# MDR1986VE3 register map
Vendor: Milandr; Series: ARMCM1; File version: 2.0
CPU: CM1 r1p0, little endian, no MPU, no FPU, 2 interrupt priority bits
Registers are 32-bit, read-write, reset 0x0 unless marked. A register's access mark holds for its fields unless they carry their own. Offsets are from the block's base; [hi:lo] are bit positions; {n}, {i} and the like mark numbered series; 'fields as' and 'values as' point back to an identical list.

## MDR_RST_CLOCK — CLock Control
Base 0x40020000
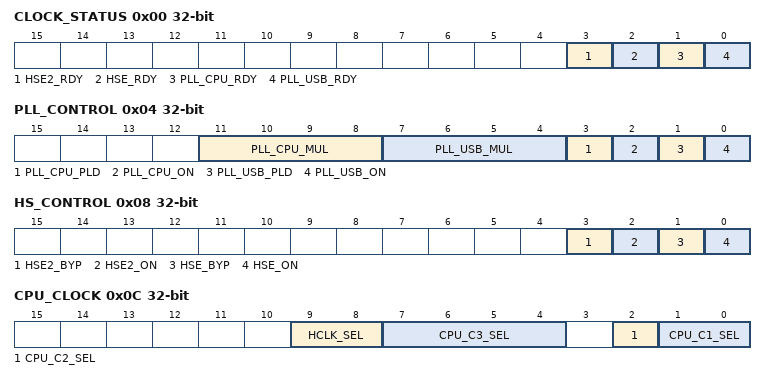
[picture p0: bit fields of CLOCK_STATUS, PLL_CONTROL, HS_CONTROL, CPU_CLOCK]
0x00 CLOCK_STATUS ro
  [3] HSE2_RDY — HSE2 generator ready
    0=NotReady (HSE2 not ready); 1=Ready (HSE2 ready)
  [2] HSE_RDY — HSE generator ready
    0=NotReady (HSE not ready); 1=Ready (HSE ready)
  [1] PLL_CPU_RDY — PLL CPU ready
    0=NotReady (PLL not ready); 1=Ready (PLL ready)
  [0] PLL_USB_RDY — PLL USP ready
    0=NotReady (PLL not ready); 1=Ready (PLL ready)
0x04 PLL_CONTROL
  [11:8] PLL_CPU_MUL — PLL CPU Mul, [x1 .. x16]
    0=PLL mul x1; {v}=x{v+1} (PLL mul x{v+1}) (v=1..8); 9=PLL mul x10; 10=PLL mul x11; {v}=x{v+1} (PLL mul x{v+1}) (v=11..15)
  [7:4] PLL_USB_MUL — PLL USB Mul, [x1 .. x16]
    values as PLL_CPU_MUL
  [3] PLL_CPU_PLD — PLL CPU Restart
    0=RestartOff (PLL restart inactive); 1=DoRestart (PLL Do Restart)
  [2] PLL_CPU_ON — PLL CPU Enable
    0=Off (PLL Off); 1=On (PLL On)
  [1] PLL_USB_PLD — PLL USB Restart
    values as PLL_CPU_PLD
  [0] PLL_USB_ON — PLL USB Enable
    0=Off (PLL Off); 1=On (PLL On)
0x08 HS_CONTROL — HSE Generator Control
  [3] HSE2_BYP — HSE2 Bypass Mode
    0=Off (HSE2 forms Clock from external oscillator); 1=On (HSE2 passes Clock from external generator)
  [2] HSE2_ON — HSE2 Enable
    0=Off (HSE2 Off); 1=On (HSE2 On)
  [1] HSE_BYP — HSE Bypass Mode
    0=Off (HSE forms Clock from external oscillator); 1=On (HSE passes Clock from external generator)
  [0] HSE_ON — HSE Enable
    0=Off (HSE Off); 1=On (HSE On)
0x0C CPU_CLOCK — CPU Clock Control
  [9:8] HCLK_SEL — Select Clock for CPU
    0=HSI (CPU clock is HSI); 1=CPU_C3 (CPU clock is CPU_C3 output); 2=LSE (CPU clock is LSE); 3=LSI (CPU clock is LSI)
  [7:4] CPU_C3_SEL — CPU_C2 mux output freq devider, [/1, /2, /4 .. /256]
    0b0xxx=div1 (div by 1); 8=div2 (div by 2); 9=div4 (div by 4); 10=div8 (div by 8); 11=div16 (div by 16); 12=div32 (div by 32); 13=div64 (div by 64); 14=div128 (div by 128); 15=div256 (div by 256)
  [2] CPU_C2_SEL — CPU_C2 mux freq select
    0=CPU_C1 (Freq from CPU_C1 mux direct); 1=PLLCPUo (Freq from CPU_C1 mux through PLL)
  [1:0] CPU_C1_SEL — CPU_C1 mux freq select
    0=HSI (CPU_C1 output is HSI); 1=HSI/2 (CPU_C1 output is HSI/2); 2=HSE (CPU_C1 output is HSE); 3=HSE/2 (CPU_C1 output is HSE/2)
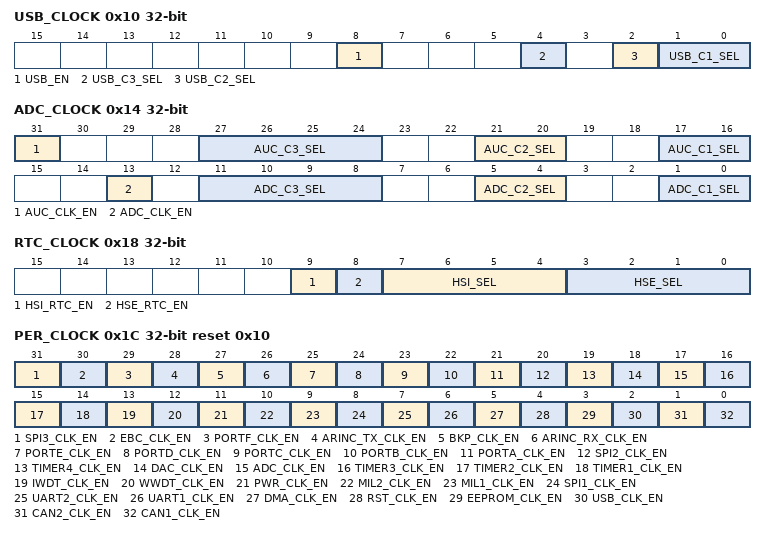
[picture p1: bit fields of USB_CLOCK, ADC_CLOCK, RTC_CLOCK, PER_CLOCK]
0x10 USB_CLOCK — USB Clock Control
  [8] USB_EN — USB Clock Enable
    0=Off (Clock Disabled); 1=On (Clock Enabled)
  [4] USB_C3_SEL — USB_C3 Input Select
    0=USB_C2 (C3 Input is freq from C2); 1=USB_C2_div2 (C3 Input is freq from C2/2)
  [2] USB_C2_SEL — USB_C2 mux freq select
    0=USB_C1 (Freq from CPU_C1 mux direct); 1=PLLUSBo (Freq from CPU_C1 mux through PLL_USB)
  [1:0] USB_C1_SEL — USB_C1 mux freq select
    0=HSI (USB_C1 output is HSI); 1=HSI/2 (USB_C1 output is HSI/2); 2=HSE (USB_C1 output is HSE); 3=HSE/2 (USB_C1 output is HSE/2)
0x14 ADC_CLOCK — ADC Clock Control
  [31] AUC_CLK_EN — AudioCodec Clock Enable
    0=Off (AUC clock disabled); 1=On (AUC clock enabled)
  [27:24] AUC_C3_SEL — AUC_C3 mux input select
    values as CPU_CLOCK.CPU_C3_SEL
  [21:20] AUC_C2_SEL — AUC_C2 mux input select
    0=AUC_C1 (AUC_C2 output is AUC_C1 select); 1=PLLCPUo (AUC_C2 output is PLLCPUo); 2=PLLUSBo (AUC_C2 output is PLLUSBo); 3=No signal from AUC_C2
  [17:16] AUC_C1_SEL — AUC_C1 mux input select
    values as CPU_CLOCK.CPU_C1_SEL
  [13] ADC_CLK_EN — ADC Clock Enable
    0=Off (ADC clock disabled); 1=On (ADC clock enabled)
  [11:8] ADC_C3_SEL — ADC_C2 mux output freq devider, [/1, /2, /4 .. /256]
    values as CPU_CLOCK.CPU_C3_SEL
  [5:4] ADC_C2_SEL — ADC_C2 mux freq select
    0=LSE (ADC_C2 output is LSE); 1=LSI (ADC_C2 output is LSI); 2=ADC_C1 (ADC_C2 output is ADC_C1); 3=HSI_C1 (ADC_C2 output is HSI_C1)
  [1:0] ADC_C1_SEL — ADC_C1 mux freq select
    0=CPU_C1 (ADC_C1 output is CPU_C1); 1=USB_C1 (ADC_C1 output is USB_C1); 2=CPU_C2 (ADC_C1 output is CPU_C2); 3=USB_C2 (ADC_C1 output is USB_C2)
0x18 RTC_CLOCK — RTC Clock Control
  [9] HSI_RTC_EN — RTC HSI Clock enable
    0=Off (RTC HSI Clock Disabled); 1=On (RTC HSI Clock Enabled)
  [8] HSE_RTC_EN — RTC HSE Clock enable
    0=Off (RTC HSE Clock Disabled); 1=On (RTC HSE Clock Enabled)
  [7:4] HSI_SEL — RTC HSI freq devider, [/1, /2, /4 .. /256]
    values as CPU_CLOCK.CPU_C3_SEL
  [3:0] HSE_SEL — RTC HSE freq devider, [/1, /2, /4 .. /256]
    values as CPU_CLOCK.CPU_C3_SEL
0x1C PER_CLOCK reset 0x10 — Peripherials Clock Control
  [all] fields
    0=Off (Clock Disabled); 1=On (Clock Enabled)
  [31] SPI3_CLK_EN — SPI3 Clock Enable
  [30] EBC_CLK_EN — External Bus Clock Enable
  [29] PORTF_CLK_EN — GPIO PORT_F Clock Enable
  [28] ARINC_TX_CLK_EN — ARINC_TX Clock Enable
  [27] BKP_CLK_EN — Backup Clock Enable
  [26] ARINC_RX_CLK_EN — ARINC_RX Clock Enable
  [25] PORTE_CLK_EN — GPIO PORT_E Clock Enable
  [24] PORTD_CLK_EN — GPIO PORT_D Clock Enable
  [23] PORTC_CLK_EN — GPIO PORT_C Clock Enable
  [22] PORTB_CLK_EN — GPIO PORT_B Clock Enable
  [21] PORTA_CLK_EN — GPIO PORT_A Clock Enable
  [20] SPI2_CLK_EN — SPI2 Clock Enable
  [19] TIMER4_CLK_EN — TIMER4 Clock Enable
  [18] DAC_CLK_EN — DAC Clock Enable
  [17] ADC_CLK_EN — ADC Clock Enable
  [16] TIMER3_CLK_EN — TIMER3 Clock Enable
  [15] TIMER2_CLK_EN — TIMER2 Clock Enable
  [14] TIMER1_CLK_EN — TIMER1 Clock Enable
  [13] IWDT_CLK_EN — IWDT Clock Enable
  [12] WWDT_CLK_EN — WWDT Clock Enable
  [11] PWR_CLK_EN — Power Clock Enable
  [10] MIL2_CLK_EN — MIL2 Clock Enable
  [9] MIL1_CLK_EN — MIL1 Clock Enable
  [8] SPI1_CLK_EN — SPI1 Clock Enable
  [7] UART2_CLK_EN — UART2 Clock Enable
  [6] UART1_CLK_EN — UART1 Clock Enable
  [5] DMA_CLK_EN — DMA Clock Enable
  [4] RST_CLK_EN — RST Clock Enable
  [3] EEPROM_CLK_EN — EEPROM Controller Clock Enable
  [2] USB_CLK_EN — USB Clock Enable
  [1] CAN2_CLK_EN — CAN2 Clock Enable
  [0] CAN1_CLK_EN — CAN1 Clock Enable
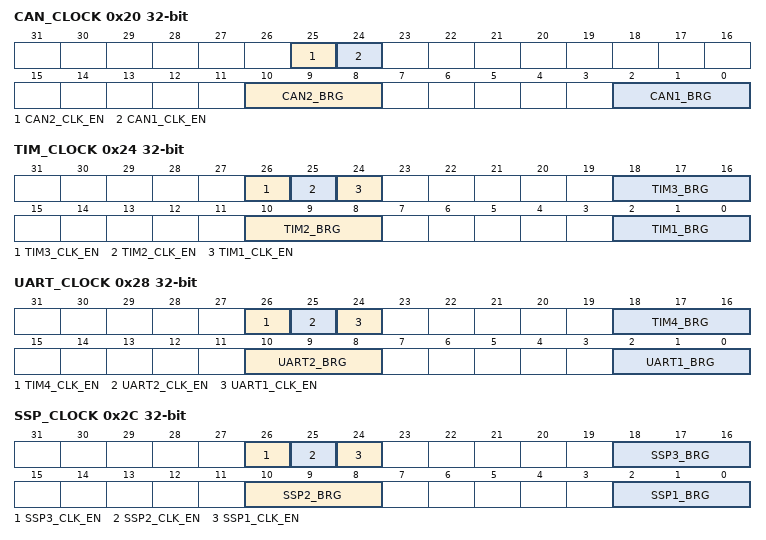
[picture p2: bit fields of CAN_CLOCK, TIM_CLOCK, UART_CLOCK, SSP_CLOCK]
0x20 CAN_CLOCK — CAN's Clock Control
  [25] CAN2_CLK_EN — CAN2_CLOCK enable
    0=Off (CAN2 Clock Disabled); 1=On (CAN2 Clock Enabled)
  [24] CAN1_CLK_EN — CAN1_CLOCK enable
    0=Off (CAN1 Clock Disabled); 1=On (CAN1 Clock Enabled)
  [10:8] CAN2_BRG — HCLK freq divider to get CAN2_CLOCK, [/1, /2, /4 .. /128]
    0=div1 (div by 1); 1=div2 (div by 2); 2=div4 (div by 4); 3=div8 (div by 8); 4=div16 (div by 16); 5=div32 (div by 32); 6=div64 (div by 64); 7=div128 (div by 128)
  [2:0] CAN1_BRG — HCLK divider to get CAN1_CLOCK, [/1, /2, /4 .. /128]
    values as CAN2_BRG
0x24 TIM_CLOCK — Timer's Clock Control
  [26] TIM3_CLK_EN — TIM3_CLOCK enable
    0=Off (Timer3 Clock Disabled); 1=On (Timer3 Clock Enabled)
  [25] TIM2_CLK_EN — TIM2_CLOCK enable
    0=Off (Timer2 Clock Disabled); 1=On (Timer2 Clock Enabled)
  [24] TIM1_CLK_EN — TIM1_CLOCK enable
    0=Off (Timer1 Clock Disabled); 1=On (Timer1 Clock Enabled)
  [18:16] TIM3_BRG — HCLK freq divider to get TIM3_CLOCK, [/1, /2, /4 .. /128]
    values as CAN_CLOCK.CAN2_BRG
  [10:8] TIM2_BRG — HCLK freq divider to get TIM2_CLOCK, [/1, /2, /4 .. /128]
    values as CAN_CLOCK.CAN2_BRG
  [2:0] TIM1_BRG — HCLK freq divider to get TIM1_CLOCK, [/1, /2, /4 .. /128]
    values as CAN_CLOCK.CAN2_BRG
0x28 UART_CLOCK — UART's Clock Control
  [26] TIM4_CLK_EN — TIM4_CLOCK enable
    0=Off (Timer4 Clock Disabled); 1=On (Timer4 Clock Enabled)
  [25] UART2_CLK_EN — UART2_CLOCK enable
    0=Off (UART2 Clock Disabled); 1=On (UART2 Clock Enabled)
  [24] UART1_CLK_EN — UART1_CLOCK enable
    0=Off (UART1 Clock Disabled); 1=On (UART1 Clock Enabled)
  [18:16] TIM4_BRG — HCLK freq divider to get TIM4_CLOCK, [/1, /2, /4 .. /128]
    values as CAN_CLOCK.CAN2_BRG
  [10:8] UART2_BRG — HCLK freq divider to get UART2_CLOCK, [/1, /2, /4 .. /128]
    values as CAN_CLOCK.CAN2_BRG
  [2:0] UART1_BRG — HCLK freq divider to get UART1_CLOCK, [/1, /2, /4 .. /128]
    values as CAN_CLOCK.CAN2_BRG
0x2C SSP_CLOCK — SSP's Clock Control
  [26] SSP3_CLK_EN — SSP3_CLOCK Enable
    0=Off (SSP3 Clock Disabled); 1=On (SSP3 Clock Enabled)
  [25] SSP2_CLK_EN — SSP2_CLOCK Enable
    0=Off (SSP2 Clock Disabled); 1=On (SSP2 Clock Enabled)
  [24] SSP1_CLK_EN — SSP1_CLOCK Enable
    0=Off (SSP1 Clock Disabled); 1=On (SSP1 Clock Enabled)
  [18:16] SSP3_BRG — HCLK freq divider to get SSP3_CLOCK, [/1, /2, /4 .. /128]
    values as CAN_CLOCK.CAN2_BRG
  [10:8] SSP2_BRG — HCLK freq divider to get SSP2_CLOCK, [/1, /2, /4 .. /128]
    values as CAN_CLOCK.CAN2_BRG
  [2:0] SSP1_BRG — HCLK freq divider to get SSP1_CLOCK, [/1, /2, /4 .. /128]
    values as CAN_CLOCK.CAN2_BRG
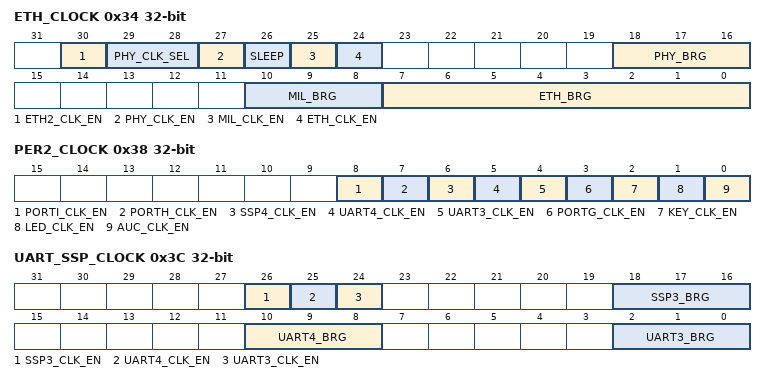
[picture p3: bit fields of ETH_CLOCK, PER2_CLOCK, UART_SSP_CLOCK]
0x34 ETH_CLOCK — Ethernet and MIL Clock Control
  [30] ETH2_CLK_EN — Ethernet2 MAC Clock Enable
    0=Off (MAC Clock Disabled); 1=On (MAC Clock Enabled)
  [29:28] PHY_CLK_SEL — Ethernet PHY CLOCK Select
    0=HSI (PHY Clock from HSI); 1=HSE (PHY Clock from HSE); 2=PLLCPUo (PHY Clock from PLLCPUo); 3=HSE2 (PHY Clock from HSE2)
  [27] PHY_CLK_EN — Ethernet PHY CLOCK Enable
    0=Off (MIL Clock Disabled); 1=On (MIL Clock Enabled)
  [26] SLEEP — Switch to Sleep mode
    0=Off (Normal Mode); 1=GoSLEEP (Go to SLEEP)
  [25] MIL_CLK_EN — MIL-STD CLOCK Enable
    0=Off (MIL Clock Disabled); 1=On (MIL Clock Enabled)
  [24] ETH_CLK_EN — Ethernet MAC Clock Enable
    0=Off (MAC Clock Disabled); 1=On (MAC Clock Enabled)
  [18:16] PHY_BRG — HCLK freq divider to get PHY_CLOCK, [/1, /2, /4 .. /128]
    values as CAN_CLOCK.CAN2_BRG
  [10:8] MIL_BRG — HCLK freq divider to get MAN_CLOCK, [/1, /2, /4 .. /128]
    values as CAN_CLOCK.CAN2_BRG
  [7:0] ETH_BRG — Always set to 0!
0x38 PER2_CLOCK — Peripherials Clock Control 2
  [all] fields
    0=Off (Clock Disabled); 1=On (Clock Enabled)
  [8] PORTI_CLK_EN — PORT_I Clock Enable
  [7] PORTH_CLK_EN — PORT_H Clock Enable
  [6] SSP4_CLK_EN — SSP4 Clock Enable
  [5] UART4_CLK_EN — UART4 Clock Enable
  [4] UART3_CLK_EN — UART3 Clock Enable
  [3] PORTG_CLK_EN — PORT_G Clock Enable
  [2] KEY_CLK_EN — Keyboard Clock Enable
  [1] LED_CLK_EN — LED Clock Enable
  [0] AUC_CLK_EN — AudioCodec Clock Enable
0x3C UART_SSP_CLOCK — UART and SSP Clock Control
  [26] SSP3_CLK_EN — SSP3_CLOCK enable
    0=Off (SSP3 Clock Disabled); 1=On (SSP3 Clock Enabled)
  [25] UART4_CLK_EN — UART4_CLOCK enable
    0=Off (UART4 Clock Disabled); 1=On (UART4 Clock Enabled)
  [24] UART3_CLK_EN — UART3_CLOCK enable
    0=Off (UART3 Clock Disabled); 1=On (UART3 Clock Enabled)
  [18:16] SSP3_BRG — HCLK freq divider to get SSP3_CLOCK, [/1, /2, /4 .. /128]
    values as CAN_CLOCK.CAN2_BRG
  [10:8] UART4_BRG — HCLK freq divider to get UART4_CLOCK, [/1, /2, /4 .. /128]
    values as CAN_CLOCK.CAN2_BRG
  [2:0] UART3_BRG — HCLK freq divider to get UART3_CLOCK, [/1, /2, /4 .. /128]
    values as CAN_CLOCK.CAN2_BRG
